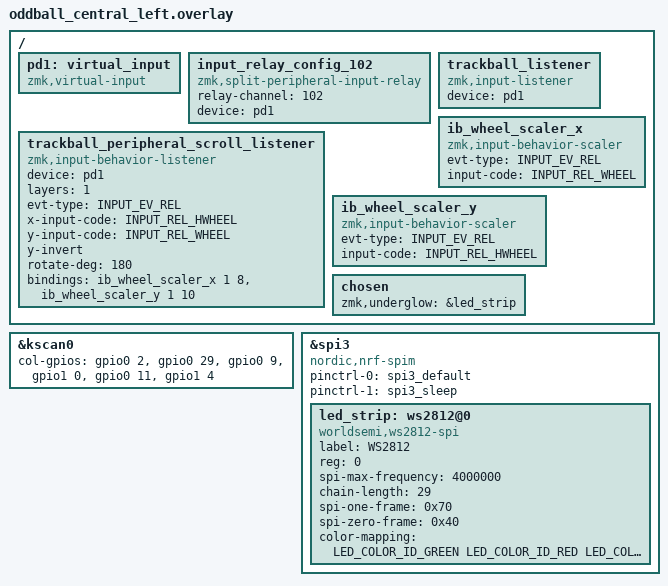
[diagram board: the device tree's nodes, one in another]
/*
 * Copyright (c) 2020 ZMK Contributors
 *
 * SPDX-License-Identifier: MIT
 */
#include <dt-bindings/led/led.h>
#include "oddball.dtsi"

#define INPUT_EV_KEY 0x01               /**< Key event */
#define INPUT_EV_REL 0x02               /**< Relative coordinate event */
#define INPUT_EV_ABS 0x03               /**< Absolute coordinate event */
#define INPUT_EV_MSC 0x04               /**< Miscellaneous event */
#define INPUT_EV_VENDOR_START 0xf0      /**< Vendor specific event start */
#define INPUT_EV_VENDOR_STOP 0xff       /**< Vendor specific event stop */

#define INPUT_REL_X 0x00                /**< Relative X coordinate */
#define INPUT_REL_Y 0x01                /**< Relative Y coordinate */
#define INPUT_REL_WHEEL 0x08            /**< Relative wheel coordinate */
#define INPUT_REL_HWHEEL 0x06           /**< Relative horizontal wheel coordinate */
#define INPUT_REL_MISC 0x09             /**< Relative misc coordinate */

&kscan0 {
	col-gpios
		= <&gpio0 2 (GPIO_ACTIVE_HIGH | GPIO_PULL_DOWN)>
		, <&gpio0 29 (GPIO_ACTIVE_HIGH | GPIO_PULL_DOWN)>
		, <&gpio0 9 (GPIO_ACTIVE_HIGH | GPIO_PULL_DOWN)>
		, <&gpio1 0  (GPIO_ACTIVE_HIGH | GPIO_PULL_DOWN)>
		, <&gpio0 11 (GPIO_ACTIVE_HIGH | GPIO_PULL_DOWN)>
		, <&gpio1 4  (GPIO_ACTIVE_HIGH | GPIO_PULL_DOWN)>
		;
};

#include "oddball_trackball.dtsi"

/ {
		pd1: virtual_input {
		compatible = "zmk,virtual-input";
	};
};

/ {
		input_relay_config_102 {
		compatible = "zmk,split-peripheral-input-relay";
		relay-channel = <102>;
		device = <&pd1>;
	};
};

/{
  trackball_listener { 
    compatible = "zmk,input-listener";
    device = <&pd1>;
  };
};

/{
     trackball_peripheral_scroll_listener {
           compatible = "zmk,input-behavior-listener";
           device = <&pd1>;
           layers = <1>;
           evt-type = <INPUT_EV_REL>;
           x-input-code = <INPUT_REL_HWHEEL>;
           y-input-code = <INPUT_REL_WHEEL>;   
           y-invert;
           rotate-deg = <180>;
           bindings = <&ib_wheel_scaler_x 1 8 &ib_wheel_scaler_y 1 10>;
   };
 ib_wheel_scaler_x: ib_wheel_scaler_x {
        compatible = "zmk,input-behavior-scaler";
        #binding-cells = <2>;
        evt-type = <INPUT_EV_REL>;
        input-code = <INPUT_REL_WHEEL>;
    };

    ib_wheel_scaler_y: ib_wheel_scaler_y {
        compatible = "zmk,input-behavior-scaler";
        #binding-cells = <2>;
        evt-type = <INPUT_EV_REL>;
        input-code = <INPUT_REL_HWHEEL>;
    };
};
&spi3 {
	compatible = "nordic,nrf-spim";
	status = "okay";

	pinctrl-0 = <&spi3_default>;
	pinctrl-1 = <&spi3_sleep>;
	pinctrl-names = "default", "sleep";


	led_strip: ws2812@0 {
		compatible = "worldsemi,ws2812-spi";
		label = "WS2812";

		/* SPI */
		reg = <0>; /* ignored, but necessary for SPI bindings */
		spi-max-frequency = <4000000>;

		/* WS2812 */
		chain-length = <29>; /* There are per-key RGB, but the first 6 are underglow */
		spi-one-frame = <0x70>;
		spi-zero-frame = <0x40>;
		color-mapping = <LED_COLOR_ID_GREEN LED_COLOR_ID_RED LED_COLOR_ID_BLUE>;
	};
};

/ {
	chosen {
		zmk,underglow = &led_strip;
	};
};
